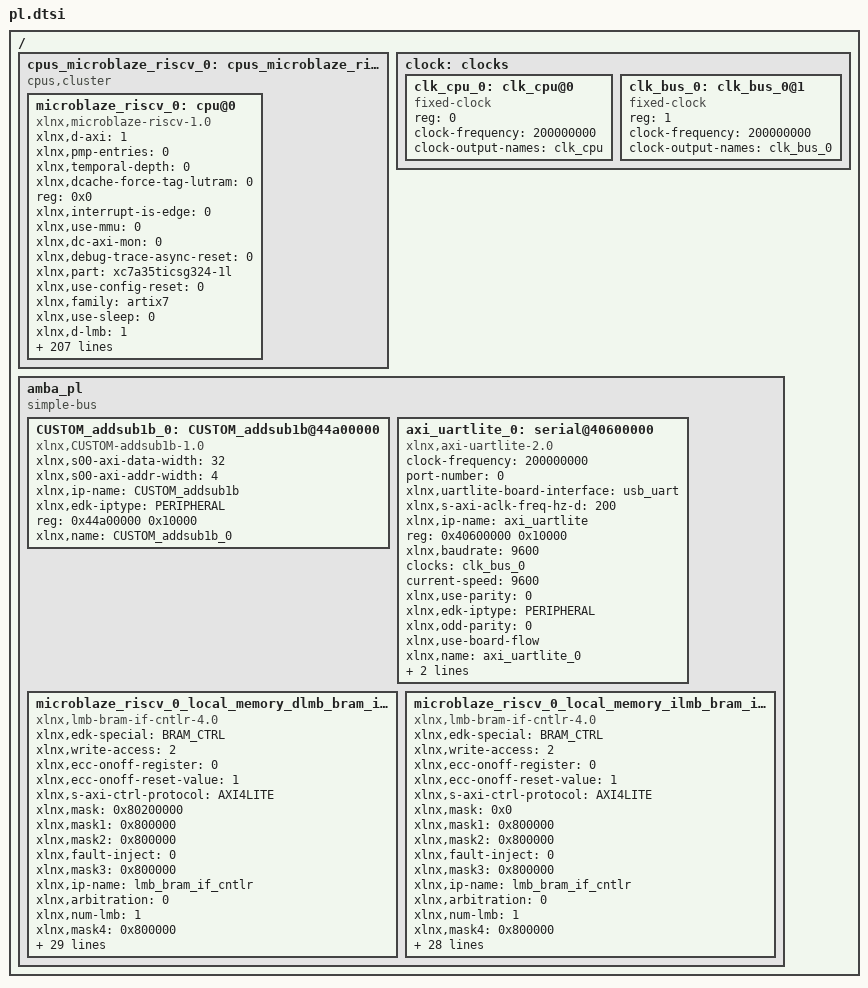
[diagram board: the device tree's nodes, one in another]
/ {
	cpus_microblaze_riscv_0: cpus_microblaze_riscv@0 {
		#cpu-mask-cells = <1>;
		compatible = "cpus,cluster";
		#address-cells = <1>;
		bootph-all;
		#size-cells = <0>;
		microblaze_riscv_0: cpu@0 {
			xlnx,d-axi = <1>;
			xlnx,pmp-entries = <0>;
			xlnx,temporal-depth = <0>;
			xlnx,dcache-force-tag-lutram = <0>;
			reg = <0x0>;
			xlnx,interrupt-is-edge = <0>;
			xlnx,use-mmu = <0>;
			xlnx,dc-axi-mon = <0>;
			xlnx,debug-trace-async-reset = <0>;
			xlnx,part = "xc7a35ticsg324-1l";
			xlnx,use-config-reset = <0>;
			xlnx,family = "artix7";
			xlnx,use-sleep = <0>;
			xlnx,d-lmb = <1>;
			xlnx,enable-discrete-ports = <0>;
			xlnx,debug-interface = <0>;
			xlnx,use-ext-brk = <0>;
			xlnx,debug-enabled = <1>;
			xlnx,daddr-size = <32>;
			xlnx,use-extended-fsl-instr = <0>;
			xlnx,branch-target-cache-size = <0>;
			bus-handle = <&amba_pl>;
			xlnx,pmp-addr0 = <0x0>;
			xlnx,pmp-addr1 = <0x0>;
			xlnx,pmp-addr2 = <0x0>;
			xlnx,pmp-addr3 = <0x0>;
			xlnx,pmp-addr4 = <0x0>;
			xlnx,edk-special = "microblaze_riscv";
			xlnx,use-dcache = <0>;
			xlnx,pmp-addr5 = <0x0>;
			xlnx,use-muldiv = <0>;
			xlnx,pmp-addr6 = <0x0>;
			xlnx,use-axi-dp-ext-addr = <0>;
			xlnx,pmp-addr7 = <0x0>;
			xlnx,pmp-addr8 = <0x0>;
			xlnx,pmp-addr9 = <0x0>;
			xlnx,i-axi = <0>;
			xlnx,icache-streams = <0>;
			xlnx,use-embedded = <0>;
			xlnx,i-lmb-has-prot = <0>;
			xlnx,num-sync-ff-dbg-clk = <1>;
			xlnx,icache-byte-size = <8192>;
			xlnx,pmp-addr10 = <0x0>;
			d-cache-size = <8192>;
			xlnx,pmp-addr11 = <0x0>;
			xlnx,pmp-addr12 = <0x0>;
			xlnx,pmp-addr13 = <0x0>;
			xlnx,pmp-addr14 = <0x0>;
			xlnx,pmp-addr15 = <0x0>;
			bootph-all;
			xlnx,avoid-primitives = <0>;
			xlnx,pmp-addr16 = <0x0>;
			xlnx,pmp-addr17 = <0x0>;
			xlnx,pmp-addr18 = <0x0>;
			xlnx,pdaddr-size = <32>;
			xlnx,pmp-addr19 = <0x0>;
			xlnx,pmp-addr20 = <0x0>;
			xlnx,pmp-addr21 = <0x0>;
			xlnx,i-lmb = <1>;
			xlnx,pmp-addr22 = <0x0>;
			xlnx,lmb-data-size = <32>;
			xlnx,lockstep-select = <0>;
			xlnx,pmp-addr23 = <0x0>;
			timebase-frequency = <200000000>;
			xlnx,pmp-addr24 = <0x0>;
			xlnx,dcache-data-width = <0>;
			xlnx,icache-force-tag-lutram = <0>;
			xlnx,pmp-addr25 = <0x0>;
			xlnx,use-branch-target-cache = <0>;
			xlnx,pmp-addr26 = <0x0>;
			xlnx,pmp-addr27 = <0x0>;
			xlnx,number-of-pc-brk = <1>;
			xlnx,pmp-addr28 = <0x0>;
			xlnx,imprecise-exceptions = <0>;
			xlnx,pmp-addr29 = <0x0>;
			xlnx,pmp-addr30 = <0x0>;
			xlnx,pmp-addr31 = <0x0>;
			xlnx,pmp-addr32 = <0x0>;
			model = "microblaze_riscv,1.0";
			xlnx,pmp-addr33 = <0x0>;
			xlnx,pmp-addr34 = <0x0>;
			xlnx,pmp-addr35 = <0x0>;
			xlnx,pmp-addr36 = <0x0>;
			d-cache-highaddr = <0x3fffffff>;
			xlnx,optimization = <0>;
			xlnx,pmp-addr37 = <0x0>;
			xlnx,pmp-addr38 = <0x0>;
			xlnx,pmp-addr39 = <0x0>;
			xlnx,pmp-addr40 = <0x0>;
			xlnx,pmp-addr41 = <0x0>;
			xlnx,d-lmb-mon = <0>;
			xlnx,pmp-addr42 = <0x0>;
			xlnx,pmp-addr43 = <0x0>;
			xlnx,pmp-addr44 = <0x0>;
			xlnx,pmp-addr45 = <0x0>;
			xlnx,pmp-addr46 = <0x0>;
			xlnx,pmp-addr47 = <0x0>;
			xlnx,pmp-addr48 = <0x0>;
			xlnx,fault-tolerant = <0>;
			xlnx,pmp-addr49 = <0x0>;
			xlnx,pmp-addr50 = <0x0>;
			xlnx,pmp-addr51 = <0x0>;
			xlnx,pmp-enhancements = <0>;
			d-cache-line-size = <16>;
			xlnx,mmu-privileged-instr = <0>;
			xlnx,pmp-addr52 = <0x0>;
			clock-frequency = <200000000>;
			xlnx,pmp-addr53 = <0x0>;
			xlnx,pmp-addr54 = <0x0>;
			xlnx,pmp-addr55 = <0x0>;
			xlnx,i-lmb-protocol = <0>;
			xlnx,pmp-addr56 = <0x0>;
			xlnx,pmp-addr57 = <0x0>;
			riscv,isa = "rv32i";
			xlnx,dp-axi-mon = <0>;
			xlnx,pmp-addr58 = <0x0>;
			xlnx,pmp-addr59 = <0x0>;
			xlnx,pmp-addr60 = <0x0>;
			xlnx,pmp-addr61 = <0x0>;
			xlnx,pmp-addr62 = <0x0>;
			xlnx,pmp-addr63 = <0x0>;
			xlnx,debug-external-trace = <0>;
			xlnx,addr-size = <32>;
			xlnx,debug-num-progbuf = <2>;
			xlnx,debug-event-counters = <0>;
			xlnx,edk-iptype = "PROCESSOR";
			xlnx,debug-latency-counters = <0>;
			xlnx,interconnect = <2>;
			xlnx,edge-is-positive = <1>;
			xlnx,use-icache = <0>;
			xlnx,async-wakeup = <3>;
			xlnx,s-axi = <0>;
			xlnx,use-ext-nm-brk = <0>;
			xlnx,ic-axi-mon = <0>;
			xlnx,archid = <0x1>;
			xlnx,num-sync-ff-clk-irq = <1>;
			xlnx,freq = <200000000>;
			xlnx,lockstep-master = <0>;
			xlnx,pmp-cfg0 = <0x0>;
			xlnx,pmp-cfg1 = <0x0>;
			xlnx,iaddr-size = <32>;
			xlnx,interrupt-mon = <0>;
			xlnx,pmp-cfg2 = <0x0>;
			xlnx,number-of-wr-addr-brk = <0>;
			xlnx,pmp-cfg3 = <0x0>;
			xlnx,pmp-cfg4 = <0x0>;
			xlnx,use-interrupt = <0>;
			xlnx,pmp-cfg5 = <0x0>;
			xlnx,async-interrupt = <1>;
			xlnx,pc-width = <14>;
			xlnx,pmp-cfg6 = <0x0>;
			xlnx,icache-victims = <0>;
			xlnx,pmp-cfg7 = <0x0>;
			xlnx,pmp-cfg8 = <0x0>;
			xlnx,pmp-cfg9 = <0x0>;
			xlnx,use-bitman-a = <0>;
			xlnx,use-bitman-b = <0>;
			xlnx,use-bitman-c = <0>;
			i-cache-baseaddr = <0x0>;
			xlnx,i-lmb-mon = <0>;
			xlnx,dcache-byte-size = <8192>;
			xlnx,data-size = <32>;
			compatible = "xlnx,microblaze-riscv-1.0" , "amd,mbv32" , "riscv" , "xlnx,microblaze_riscv";
			xlnx,pmp-debug-inhibit = <0x0>;
			xlnx,use-sstc = <1>;
			xlnx,fsl-exception = <0>;
			riscv,isa-base = "rv32i";
			xlnx,dcache-use-writeback = <0>;
			device_type = "cpu";
			xlnx,impid = <0x1>;
			xlnx,use-bitman-s = <0>;
			xlnx,base-vectors = <0x0>;
			xlnx,icache-line-len = <4>;
			xlnx,d-lmb-has-prot = <0>;
			xlnx,use-barrel = <1>;
			xlnx,misaligned-exceptions = <1>;
			xlnx,piaddr-size = <32>;
			xlnx,use-bitman = <0>;
			riscv,isa-extensions = "i" , "zicsr" , "zifencei" , "zicntr";
			xlnx,dcache-line-len = <4>;
			xlnx,num-sync-ff-clk = <2>;
			i-cache-size = <8192>;
			xlnx,memory-ip-list = "microblaze_riscv_0_local_memory_ilmb_bram_if_cntlr_memory" , "microblaze_riscv_0_local_memory_dlmb_bram_if_cntlr_memory";
			xlnx,number-of-rd-addr-brk = <0>;
			xlnx,use-counters = <1>;
			xlnx,lockstep-slave = <0>;
			xlnx,pmp-cfg10 = <0x0>;
			xlnx,pmp-cfg11 = <0x0>;
			xlnx,debug-profile-size = <0>;
			xlnx,pmp-cfg12 = <0x0>;
			xlnx,pmp-cfg13 = <0x0>;
			xlnx,pmp-cfg14 = <0x0>;
			xlnx,pmp-cfg15 = <0x0>;
			xlnx,debug-counter-width = <64>;
			xlnx,icache-data-width = <0>;
			xlnx,ip-name = "microblaze_riscv";
			xlnx,ip-axi-mon = <0>;
			xlnx,d-lmb-protocol = <0>;
			xlnx,trace = <0>;
			xlnx,ill-instr-exception = <2>;
			xlnx,debug-trace-size = <0>;
			xlnx,pmp-granularity = <2>;
			xlnx,num-sync-ff-dbg-trace-clk = <2>;
			i-cache-line-size = <16>;
			xlnx,ecc-use-ce-exception = <0>;
			i-cache-highaddr = <0x3fffffff>;
			xlnx,num-sync-ff-clk-debug = <2>;
			xlnx,use-atomic = <0>;
			clocks = <&clk_cpu_0>;
			xlnx,g-template-list = <0>;
			xlnx,trap-enhancement = <0>;
			xlnx,hartid = <0x0>;
			xlnx,use-fpu = <0>;
			xlnx,use-non-secure = <0>;
			d-cache-baseaddr = <0x0>;
			xlnx,use-compression = <0>;
			xlnx,interrupt-wakeup = <0>;
			xlnx,instr-size = <32>;
			xlnx,fsl-links = <0>;
			xlnx,dcache-victims = <0>;
			xlnx,pmp-read-only = <0x0>;
		};
	};
	clock: clocks {
		#address-cells = <1>;
		#size-cells = <0>;
		clk_cpu_0: clk_cpu@0 {
			compatible = "fixed-clock";
			bootph-all;
			reg = <0>;
			clock-frequency = <200000000>;
			clock-output-names = "clk_cpu";
			#clock-cells = <0>;
		};
		clk_bus_0: clk_bus_0@1 {
			compatible = "fixed-clock";
			bootph-all;
			reg = <1>;
			clock-frequency = <200000000>;
			clock-output-names = "clk_bus_0";
			#clock-cells = <0>;
		};
	};
	amba_pl: amba_pl {
		ranges;
		compatible = "simple-bus";
		#address-cells = <1>;
		bootph-all;
		#size-cells = <1>;
		CUSTOM_addsub1b_0: CUSTOM_addsub1b@44a00000 {
			xlnx,s00-axi-data-width = <32>;
			compatible = "xlnx,CUSTOM-addsub1b-1.0";
			status = "okay";
			xlnx,s00-axi-addr-width = <4>;
			xlnx,ip-name = "CUSTOM_addsub1b";
			xlnx,edk-iptype = "PERIPHERAL";
			reg = <0x44a00000 0x10000>;
			xlnx,name = "CUSTOM_addsub1b_0";
		};
		axi_uartlite_0: serial@40600000 {
			compatible = "xlnx,axi-uartlite-2.0" , "xlnx,xps-uartlite-1.00.a";
			bootph-all;
			clock-frequency = <200000000>;
			port-number = <0>;
			xlnx,uartlite-board-interface = "usb_uart";
			xlnx,s-axi-aclk-freq-hz-d = <200>;
			xlnx,ip-name = "axi_uartlite";
			reg = <0x40600000 0x10000>;
			xlnx,baudrate = <9600>;
			clocks = <&clk_bus_0>;
			current-speed = <9600>;
			device_type = "serial";
			xlnx,use-parity = <0>;
			xlnx,edk-iptype = "PERIPHERAL";
			xlnx,odd-parity = <0>;
			status = "okay";
			xlnx,use-board-flow;
			xlnx,name = "axi_uartlite_0";
			xlnx,data-bits = <8>;
			xlnx,parity = "No_Parity";
		};
		microblaze_riscv_0_local_memory_dlmb_bram_if_cntlr: lmb_bram_if_cntlr@0 {
			xlnx,edk-special = "BRAM_CTRL";
			xlnx,write-access = <2>;
			compatible = "xlnx,lmb-bram-if-cntlr-4.0" , "xlnx,axi-bram-ctrl";
			xlnx,ecc-onoff-register = <0>;
			xlnx,ecc-onoff-reset-value = <1>;
			xlnx,s-axi-ctrl-protocol = "AXI4LITE";
			xlnx,mask = <0x80200000>;
			xlnx,mask1 = <0x800000>;
			xlnx,mask2 = <0x800000>;
			xlnx,fault-inject = <0>;
			xlnx,mask3 = <0x800000>;
			xlnx,ip-name = "lmb_bram_if_cntlr";
			xlnx,arbitration = <0>;
			xlnx,num-lmb = <1>;
			xlnx,mask4 = <0x800000>;
			reg = <0x00000000 0x4000>;
			xlnx,s-axi-ctrl-addr-width = <32>;
			xlnx,mask5 = <0x800000>;
			xlnx,ecc-status-registers = <0>;
			xlnx,prot-cfg = <0xff>;
			xlnx,mask6 = <0x800000>;
			xlnx,lmb-protocol = <0>;
			xlnx,ce-counter-width = <0>;
			xlnx,prot-cfg1 = <0xff>;
			xlnx,mask7 = <0x800000>;
			xlnx,ecc = <0>;
			xlnx,edk-iptype = "PERIPHERAL";
			xlnx,prot-cfg2 = <0xff>;
			xlnx,lmb-dwidth = <32>;
			xlnx,interconnect = <0>;
			xlnx,ce-failing-registers = <0>;
			xlnx,prot-cfg3 = <0xff>;
			xlnx,ue-failing-registers = <0>;
			xlnx,prot-cfg4 = <0xff>;
			xlnx,lmb-has-prot = <0>;
			status = "okay";
			xlnx,data-width = <32>;
			xlnx,prot-cfg5 = <0xff>;
			xlnx,s-axi-ctrl-data-width = <32>;
			xlnx,prot-cfg6 = <0xff>;
			xlnx,bram-awidth = <32>;
			xlnx,prot-cfg7 = <0xff>;
			xlnx,lmb-awidth = <32>;
			xlnx,name = "microblaze_riscv_0_local_memory_dlmb_bram_if_cntlr";
		};
		microblaze_riscv_0_local_memory_ilmb_bram_if_cntlr: microblaze_riscv_0_local_memory_ilmb_bram_if_cntlr@0 {
			xlnx,edk-special = "BRAM_CTRL";
			xlnx,write-access = <2>;
			compatible = "xlnx,lmb-bram-if-cntlr-4.0" , "xlnx,axi-bram-ctrl";
			xlnx,ecc-onoff-register = <0>;
			xlnx,ecc-onoff-reset-value = <1>;
			xlnx,s-axi-ctrl-protocol = "AXI4LITE";
			xlnx,mask = <0x0>;
			xlnx,mask1 = <0x800000>;
			xlnx,mask2 = <0x800000>;
			xlnx,fault-inject = <0>;
			xlnx,mask3 = <0x800000>;
			xlnx,ip-name = "lmb_bram_if_cntlr";
			xlnx,arbitration = <0>;
			xlnx,num-lmb = <1>;
			xlnx,mask4 = <0x800000>;
			reg = <0x00000000 0x4000>;
			xlnx,s-axi-ctrl-addr-width = <32>;
			xlnx,mask5 = <0x800000>;
			xlnx,ecc-status-registers = <0>;
			xlnx,prot-cfg = <0xff>;
			xlnx,mask6 = <0x800000>;
			xlnx,lmb-protocol = <0>;
			xlnx,ce-counter-width = <0>;
			xlnx,prot-cfg1 = <0xff>;
			xlnx,mask7 = <0x800000>;
			xlnx,ecc = <0>;
			xlnx,edk-iptype = "PERIPHERAL";
			xlnx,prot-cfg2 = <0xff>;
			xlnx,lmb-dwidth = <32>;
			xlnx,interconnect = <0>;
			xlnx,ce-failing-registers = <0>;
			xlnx,prot-cfg3 = <0xff>;
			xlnx,ue-failing-registers = <0>;
			xlnx,prot-cfg4 = <0xff>;
			xlnx,lmb-has-prot = <0>;
			status = "okay";
			xlnx,prot-cfg5 = <0xff>;
			xlnx,s-axi-ctrl-data-width = <32>;
			xlnx,prot-cfg6 = <0xff>;
			xlnx,bram-awidth = <32>;
			xlnx,prot-cfg7 = <0xff>;
			xlnx,lmb-awidth = <32>;
			xlnx,name = "microblaze_riscv_0_local_memory_ilmb_bram_if_cntlr";
		};
	};
};
